# ATtiny88 device description
Architecture: AVR8; Family: tinyAVR
Registers are 8-bit, access not given, no defined reset value unless marked. A register's access mark holds for its fields unless they carry their own. Offsets are from the block's base; [hi:lo] are bit positions; {n}, {i} and the like mark numbered series.

## PORTB — I/O Port
Instances: PORTB 0x00
0x23 PINB — Port B Input Pins
0x24 DDRB — Port B Data Direction Register
0x25 PORTB — Port B Data Register

## PORTD — I/O Port
Instances: PORTD 0x00
0x29 PIND — Port D Input Pins
0x2A DDRD — Port D Data Direction Register
0x2B PORTD — Port D Data Register

## PORTC — I/O Port
Instances: PORTC 0x00
0x26 PINC — Port C Input Pins
0x27 DDRC — Port C Data Direction Register
0x28 PORTC — Port C Data Register

## PORTA — I/O Port
Instances: PORTA 0x00
0x2C PINA bits used 3:0 — Port A Input Pins
0x2D DDRA bits used 3:0 — Port A Data Direction Register
0x2E PORTA bits used 3:0 — Port A Data Register

## SPI — Serial Peripheral Interface
Instances: SPI 0x00
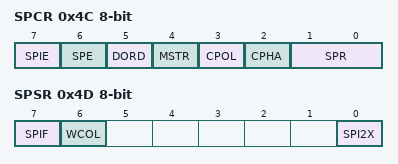
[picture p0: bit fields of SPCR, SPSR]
0x4C SPCR — SPI Control Register
  [7] SPIE — SPI Interrupt Enable
  [6] SPE — SPI Enable
  [5] DORD — Data Order
  [4] MSTR — Master/Slave Select
  [3] CPOL — Clock polarity
  [2] CPHA — Clock Phase
  [1:0] SPR — SPI Clock Rate Selects
    0=FOSC_4; 1=FOSC_16; 2=FOSC_64; 3=FOSC_128; 4=FOSC_2; 5=FOSC_8; 6=FOSC_32; 7=FOSC_64
0x4D SPSR — SPI Status Register
  [7] SPIF — SPI Interrupt Flag
  [6] WCOL — Write Collision Flag
  [0] SPI2X — Double SPI Speed Bit
0x4E SPDR — SPI Data Register

## WDT — Watchdog Timer
Instances: WDT 0x00
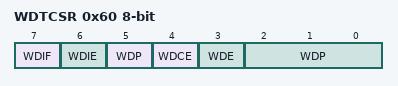
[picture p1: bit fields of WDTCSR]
0x60 WDTCSR — Watchdog Timer Control Register
  [7] WDIF — Watchdog Timeout Interrupt Flag
  [6] WDIE — Watchdog Timeout Interrupt Enable
  [4] WDCE — Watchdog Change Enable
  [3] WDE — Watch Dog Enable
  [5,2:0] WDP — Watchdog Timer Prescaler Bits
    0=OSCILLATOR_CYCLES_2K; 1=OSCILLATOR_CYCLES_4K; 2=OSCILLATOR_CYCLES_8K; 3=OSCILLATOR_CYCLES_16K; 4=OSCILLATOR_CYCLES_32K; 5=OSCILLATOR_CYCLES_64K; 6=OSCILLATOR_CYCLES_128K; 7=OSCILLATOR_CYCLES_256K; 8=OSCILLATOR_CYCLES_512K; 9=OSCILLATOR_CYCLES_1024K

## TWI — Two Wire Serial Interface
Instances: TWI 0x00
0xB8 TWBR — TWI Bit Rate register
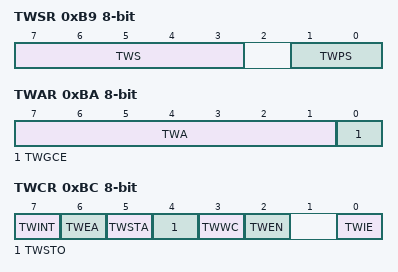
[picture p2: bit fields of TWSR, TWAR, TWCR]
0xB9 TWSR — TWI Status Register
  [7:3] TWS (bit 3 of the value upward) — TWI Status
  [1:0] TWPS — TWI Prescaler
    0=1; 1=4; 2=16; 3=64
0xBA TWAR — TWI (Slave) Address register
  [7:1] TWA — TWI (Slave) Address register Bits
  [0] TWGCE — TWI General Call Recognition Enable Bit
0xBB TWDR — TWI Data register
0xBC TWCR — TWI Control Register
  [7] TWINT — TWI Interrupt Flag
  [6] TWEA — TWI Enable Acknowledge Bit
  [5] TWSTA — TWI Start Condition Bit
  [4] TWSTO — TWI Stop Condition Bit
  [3] TWWC — TWI Write Collision Flag
  [2] TWEN — TWI Enable Bit
  [0] TWIE — TWI Interrupt Enable
0xBD TWAMR — TWI (Slave) Address Mask Register
  [7:1] TWAM
0xBE TWHSR
  [0] TWHS

## ADC — Analog-to-Digital Converter
Instances: ADC 0x00
0x78 ADC 16-bit — ADC Data Register Bytes
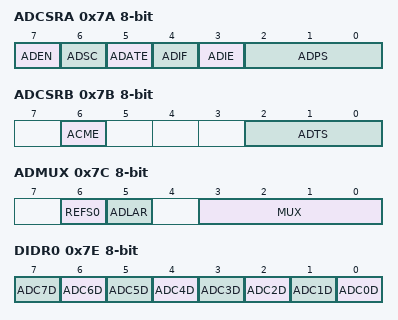
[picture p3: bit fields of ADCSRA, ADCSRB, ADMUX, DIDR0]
0x7A ADCSRA — The ADC Control and Status register A
  [7] ADEN — ADC Enable
  [6] ADSC — ADC Start Conversion
  [5] ADATE — ADC Auto Trigger Enable
  [4] ADIF — ADC Interrupt Flag
  [3] ADIE — ADC Interrupt Enable
  [2:0] ADPS — ADC Prescaler Select Bits
    0=2; 1=2; 2=4; 3=8; 4=16; 5=32; 6=64; 7=128
0x7B ADCSRB — The ADC Control and Status register B
  [6] ACME
  [2:0] ADTS — ADC Auto Trigger Source bits
    0=FREE_RUNNING_MODE; 1=ANALOG_COMPARATOR; 2=EXTERNAL_INTERRUPT_REQUEST_0; 3=TIMER_COUNTER0_COMPARE_MATCH_A; 4=TIMER_COUNTER0_OVERFLOW; 5=TIMER_COUNTER1_COMPARE_MATCH_B; 6=TIMER_COUNTER1_OVERFLOW; 7=TIMER_COUNTER1_CAPTURE_EVENT
0x7C ADMUX — The ADC multiplexer Selection Register
  [6] REFS0 — Reference Selection Bit 0
    0=INTERNAL_1_1V_VOLTAGE_REFERENCE; 1=AVCC_REFERENCE
  [5] ADLAR — Left Adjust Result
  [3:0] MUX — Analog Channel and Gain Selection Bits
0x7E DIDR0 — Digital Input Disable Register 0
  [n] ADC{n}D (n=0..7)
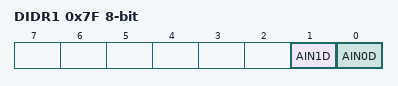
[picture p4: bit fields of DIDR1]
0x7F DIDR1 — Digital Input Disable Register 1
  [1] AIN1D, [0] AIN0D
